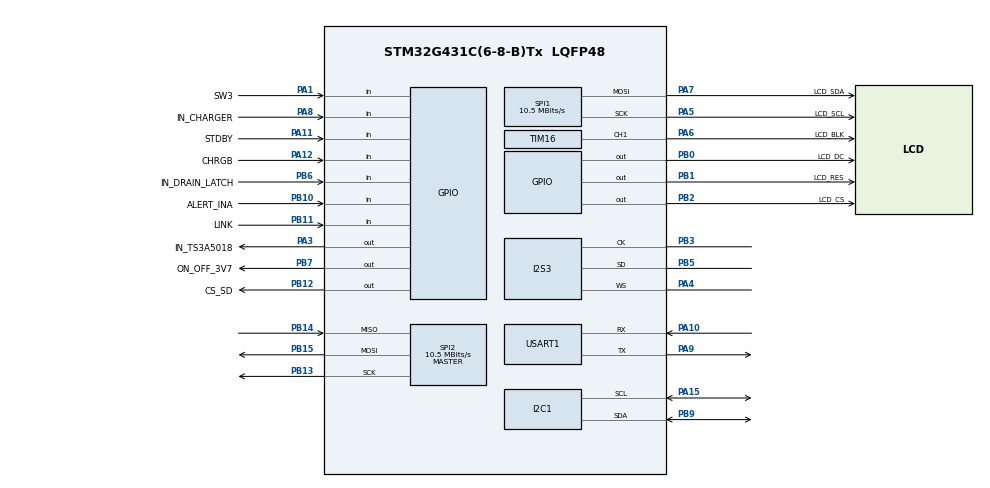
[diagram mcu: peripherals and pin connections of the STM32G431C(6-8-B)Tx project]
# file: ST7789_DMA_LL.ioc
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Dma.Request0=SPI1_TX
Dma.SPI1_TX.0.Direction=DMA_MEMORY_TO_PERIPH
Dma.SPI1_TX.0.EventEnable=DISABLE
Dma.SPI1_TX.0.Instance=DMA1_Channel1
Dma.SPI1_TX.0.MemDataAlignment=DMA_MDATAALIGN_HALFWORD
Dma.SPI1_TX.0.MemInc=DMA_MINC_ENABLE
Dma.SPI1_TX.0.Mode=DMA_NORMAL
Dma.SPI1_TX.0.PeriphDataAlignment=DMA_PDATAALIGN_HALFWORD
Dma.SPI1_TX.0.PeriphInc=DMA_PINC_DISABLE
Dma.SPI1_TX.0.Polarity=HAL_DMAMUX_REQ_GEN_RISING
Dma.SPI1_TX.0.Priority=DMA_PRIORITY_LOW
Dma.SPI1_TX.0.RequestNumber=1
Dma.SPI1_TX.0.SignalID=NONE
Dma.SPI1_TX.0.SyncEnable=DISABLE
Dma.SPI1_TX.0.SyncPolarity=HAL_DMAMUX_SYNC_NO_EVENT
Dma.SPI1_TX.0.SyncRequestNumber=1
Dma.SPI1_TX.0.SyncSignalID=NONE
FATFS._MAX_SS=4096
FATFS._USE_LFN=1
I2C1.Timing=0x20916F9D
I2S3.AudioFreq=I2S_AUDIOFREQ_44K
I2S3.ErrorAudioFreq=-0.56 %
I2S3.FullDuplexMode=I2S_FULLDUPLEXMODE_DISABLE
I2S3.Instance=SPI$Index
I2S3.RealAudioFreq=43.75 KHz
I2S3.VirtualMode=I2S_MODE_MASTER
Mcu.Family=STM32G4
Mcu.Name=STM32G431C(6-8-B)Tx
Mcu.Package=LQFP48
NVIC.DMA1_Channel1_IRQn=true\:0\:0\:false\:false\:true\:false\:true\:true
NVIC.PriorityGroup=NVIC_PRIORITYGROUP_4
PA0.Mode=SYS_WakeUp0
PA0.Signal=SYS_WKUP1
PA1.GPIO_Label=SW3
PA1.Signal=GPIO_Input
PA10.Mode=Asynchronous
PA10.Signal=USART1_RX
PA11.GPIO_Label=STDBY
PA11.Signal=GPIO_Input
PA12.GPIO_Label=CHRGB
PA12.Signal=GPIO_Input
PA13.Mode=Serial_Wire
PA13.Signal=SYS_JTMS-SWDIO
PA14.Mode=Serial_Wire
PA14.Signal=SYS_JTCK-SWCLK
PA15.Mode=I2C
PA15.Signal=I2C1_SCL
PA2.Mode=SYS_WakeUp3
PA2.Signal=SYS_WKUP4
PA3.GPIO_Label=IN_TS3A5018
PA3.Signal=GPIO_Output
PA4.Mode=Half_Duplex_Master
PA4.Signal=I2S3_WS
PA5.GPIO_Label=LCD_SCL
PA5.Mode=TX_Only_Simplex_Unidirect_Master
PA5.Signal=SPI1_SCK
PA6.GPIO_Label=LCD_BLK
PA6.Signal=S_TIM16_CH1
PA7.GPIO_Label=LCD_SDA
PA7.Mode=TX_Only_Simplex_Unidirect_Master
PA7.Signal=SPI1_MOSI
PA8.GPIO_Label=IN_CHARGER
PA8.Signal=GPIO_Input
PA9.Mode=Asynchronous
PA9.Signal=USART1_TX
PB0.GPIO_Label=LCD_DC
PB0.GPIO_Speed=GPIO_SPEED_FREQ_VERY_HIGH
PB0.Signal=GPIO_Output
PB1.GPIO_Label=LCD_RES
PB1.GPIO_Speed=GPIO_SPEED_FREQ_VERY_HIGH
PB1.Signal=GPIO_Output
PB10.GPIO_Label=ALERT_INA
PB10.GPIO_PuPd=GPIO_PULLUP
PB10.Signal=GPIO_Input
PB11.GPIO_Label=LINK
PB11.Signal=GPIO_Input
PB12.GPIO_Label=CS_SD
PB12.Signal=GPIO_Output
PB13.Mode=Full_Duplex_Master
PB13.Signal=SPI2_SCK
PB14.Mode=Full_Duplex_Master
PB14.Signal=SPI2_MISO
PB15.Mode=Full_Duplex_Master
PB15.Signal=SPI2_MOSI
PB2.GPIO_Label=LCD_CS
PB2.GPIO_Speed=GPIO_SPEED_FREQ_VERY_HIGH
PB2.PinState=GPIO_PIN_SET
PB2.Signal=GPIO_Output
PB3.Mode=Half_Duplex_Master
PB3.Signal=I2S3_CK
PB5.Mode=Half_Duplex_Master
PB5.Signal=I2S3_SD
PB6.GPIO_Label=IN_DRAIN_LATCH
PB6.Signal=GPIO_Input
PB7.GPIO_Label=ON_OFF_3V7
PB7.Signal=GPIO_Output
PB9.Mode=I2C
PB9.Signal=I2C1_SDA
PC13.Mode=SYS_WakeUp1
PC13.Signal=SYS_WKUP2
PF0-OSC_IN.Mode=HSE-External-Oscillator
PF0-OSC_IN.Signal=RCC_OSC_IN
PF1-OSC_OUT.Mode=HSE-External-Oscillator
PF1-OSC_OUT.Signal=RCC_OSC_OUT
ProjectManager.HeapSize=0x200
ProjectManager.StackSize=0x400
ProjectManager.TargetToolchain=STM32CubeIDE
RCC.ADC12Freq_Value=84000000
RCC.AHBFreq_Value=84000000
RCC.APB1Freq_Value=84000000
RCC.APB1TimFreq_Value=84000000
RCC.APB2Freq_Value=84000000
RCC.APB2TimFreq_Value=84000000
RCC.CortexFreq_Value=84000000
RCC.EXTERNAL_CLOCK_VALUE=12288000
RCC.HCLKFreq_Value=84000000
RCC.HSE_VALUE=20000000
RCC.HSI48_VALUE=48000000
RCC.HSI_VALUE=16000000
RCC.LSE_VALUE=32768
RCC.PLLM=RCC_PLLM_DIV5
RCC.PLLN=42
RCC.PLLSourceVirtual=RCC_PLLSOURCE_HSE
RCC.SYSCLKFreq_VALUE=84000000
RCC.SYSCLKSource=RCC_SYSCLKSOURCE_PLLCLK
RCC.USBFreq_Value=84000000
RCC.VCOOutputFreq_Value=168000000
SH.S_TIM16_CH1.0=TIM16_CH1,PWM Generation1 CH1
SPI1.BaudRatePrescaler=SPI_BAUDRATEPRESCALER_8
SPI1.CLKPhase=SPI_PHASE_1EDGE
SPI1.CLKPolarity=SPI_POLARITY_HIGH
SPI1.CalculateBaudRate=10.5 MBits/s
SPI1.DataSize=SPI_DATASIZE_16BIT
SPI1.Direction=SPI_DIRECTION_2LINES
SPI1.Mode=SPI_MODE_MASTER
SPI1.VirtualType=VM_MASTER
SPI2.BaudRatePrescaler=SPI_BAUDRATEPRESCALER_8
SPI2.CalculateBaudRate=10.5 MBits/s
SPI2.DataSize=SPI_DATASIZE_8BIT
SPI2.Direction=SPI_DIRECTION_2LINES
SPI2.Mode=SPI_MODE_MASTER
SPI2.VirtualType=VM_MASTER
TIM16.Channel=TIM_CHANNEL_1
TIM16.PeriodNoDither=210-1
TIM16.Prescaler=1000-1
TIM16.PulseNoDither_1=210-1
USART1.VirtualMode-Asynchronous=VM_ASYNC
VP_FATFS_VS_Generic.Mode=User_defined
VP_TIM16_VS_ClockSourceINT.Mode=Enable_Timer
board=custom

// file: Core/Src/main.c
/* USER CODE BEGIN Header */
/**
  ******************************************************************************
  * @file           : main.c
  * @brief          : Main program body
  ******************************************************************************
  * @attention
  *
  * Copyright (c) 2025 STMicroelectronics.
  * All rights reserved.
  *
  * This software is licensed under terms that can be found in the LICENSE file
  * in the root directory of this software component.
  * If no LICENSE file comes with this software, it is provided AS-IS.
  *
  ******************************************************************************
  */
/* USER CODE END Header */
#include "main.h"
#include "app_fatfs.h"

/* USER CODE BEGIN Includes */
#include "display.h"
#include "st7789.h"
/* USER CODE END Includes */

I2C_HandleTypeDef hi2c1;

I2S_HandleTypeDef hi2s3;

UART_HandleTypeDef huart1;

void SystemClock_Config(void);
static void MX_GPIO_Init(void);
static void MX_DMA_Init(void);
static void MX_I2C1_Init(void);
static void MX_SPI1_Init(void);
static void MX_TIM16_Init(void);
static void MX_SPI2_Init(void);
static void MX_I2S3_Init(void);
static void MX_USART1_UART_Init(void);

int main(void)
{

  /* MCU Configuration--------------------------------------------------------*/

  /* Reset of all peripherals, Initializes the Flash interface and the Systick. */
  HAL_Init();

  /* Configure the system clock */
  SystemClock_Config();

  /* Initialize all configured peripherals */
  MX_GPIO_Init();
  MX_DMA_Init();
  MX_I2C1_Init();
  MX_SPI1_Init();
  MX_TIM16_Init();
  MX_SPI2_Init();
  MX_I2S3_Init();
  MX_USART1_UART_Init();
  if (MX_FATFS_Init() != APP_OK) {
    Error_Handler();
  }

  /* Infinite loop */
  while (1)
  {

  }
}

void SystemClock_Config(void)
{
  LL_FLASH_SetLatency(LL_FLASH_LATENCY_2);
  while(LL_FLASH_GetLatency() != LL_FLASH_LATENCY_2)
  {
  }
  LL_PWR_SetRegulVoltageScaling(LL_PWR_REGU_VOLTAGE_SCALE1);
  LL_RCC_HSE_Enable();
   /* Wait till HSE is ready */
  while(LL_RCC_HSE_IsReady() != 1)
  {
  }

  LL_RCC_PLL_ConfigDomain_SYS(LL_RCC_PLLSOURCE_HSE, LL_RCC_PLLM_DIV_5, 42, LL_RCC_PLLR_DIV_2);
  LL_RCC_PLL_EnableDomain_SYS();
  LL_RCC_PLL_Enable();
   /* Wait till PLL is ready */
  while(LL_RCC_PLL_IsReady() != 1)
  {
  }

  LL_RCC_SetSysClkSource(LL_RCC_SYS_CLKSOURCE_PLL);
  LL_RCC_SetAHBPrescaler(LL_RCC_SYSCLK_DIV_2);
   /* Wait till System clock is ready */
  while(LL_RCC_GetSysClkSource() != LL_RCC_SYS_CLKSOURCE_STATUS_PLL)
  {
  }

  /* Insure 1us transition state at intermediate medium speed clock*/
  for (__IO uint32_t i = (170 >> 1); i !=0; i--);

  /* Set AHB prescaler*/
  LL_RCC_SetAHBPrescaler(LL_RCC_SYSCLK_DIV_1);
  LL_RCC_SetAPB1Prescaler(LL_RCC_APB1_DIV_1);
  LL_RCC_SetAPB2Prescaler(LL_RCC_APB2_DIV_1);
  LL_SetSystemCoreClock(84000000);

   /* Update the time base */
  if (HAL_InitTick (TICK_INT_PRIORITY) != HAL_OK)
  {
    Error_Handler();
  }
}

static void MX_I2C1_Init(void)
{

  hi2c1.Instance = I2C1;
  hi2c1.Init.Timing = 0x20916F9D;
  hi2c1.Init.OwnAddress1 = 0;
  hi2c1.Init.AddressingMode = I2C_ADDRESSINGMODE_7BIT;
  hi2c1.Init.DualAddressMode = I2C_DUALADDRESS_DISABLE;
  hi2c1.Init.OwnAddress2 = 0;
  hi2c1.Init.OwnAddress2Masks = I2C_OA2_NOMASK;
  hi2c1.Init.GeneralCallMode = I2C_GENERALCALL_DISABLE;
  hi2c1.Init.NoStretchMode = I2C_NOSTRETCH_DISABLE;
  if (HAL_I2C_Init(&hi2c1) != HAL_OK)
  {
    Error_Handler();
  }

  /** Configure Analogue filter
  */
  if (HAL_I2CEx_ConfigAnalogFilter(&hi2c1, I2C_ANALOGFILTER_ENABLE) != HAL_OK)
  {
    Error_Handler();
  }

  /** Configure Digital filter
  */
  if (HAL_I2CEx_ConfigDigitalFilter(&hi2c1, 0) != HAL_OK)
  {
    Error_Handler();
  }

}

static void MX_I2S3_Init(void)
{

  hi2s3.Instance = SPI3;
  hi2s3.Init.Mode = I2S_MODE_MASTER_TX;
  hi2s3.Init.Standard = I2S_STANDARD_PHILIPS;
  hi2s3.Init.DataFormat = I2S_DATAFORMAT_16B;
  hi2s3.Init.MCLKOutput = I2S_MCLKOUTPUT_DISABLE;
  hi2s3.Init.AudioFreq = I2S_AUDIOFREQ_44K;
  hi2s3.Init.CPOL = I2S_CPOL_LOW;
  if (HAL_I2S_Init(&hi2s3) != HAL_OK)
  {
    Error_Handler();
  }

}

static void MX_SPI1_Init(void)
{

  LL_SPI_InitTypeDef SPI_InitStruct = {0};

  LL_GPIO_InitTypeDef GPIO_InitStruct = {0};

  /* Peripheral clock enable */
  LL_APB2_GRP1_EnableClock(LL_APB2_GRP1_PERIPH_SPI1);

  LL_AHB2_GRP1_EnableClock(LL_AHB2_GRP1_PERIPH_GPIOA);
  /**SPI1 GPIO Configuration
  PA5   ------> SPI1_SCK
  PA7   ------> SPI1_MOSI
  */
  GPIO_InitStruct.Pin = LCD_SCL_Pin;
  GPIO_InitStruct.Mode = LL_GPIO_MODE_ALTERNATE;
  GPIO_InitStruct.Speed = LL_GPIO_SPEED_FREQ_LOW;
  GPIO_InitStruct.OutputType = LL_GPIO_OUTPUT_PUSHPULL;
  GPIO_InitStruct.Pull = LL_GPIO_PULL_NO;
  GPIO_InitStruct.Alternate = LL_GPIO_AF_5;
  LL_GPIO_Init(LCD_SCL_GPIO_Port, &GPIO_InitStruct);

  GPIO_InitStruct.Pin = LCD_SDA_Pin;
  GPIO_InitStruct.Mode = LL_GPIO_MODE_ALTERNATE;
  GPIO_InitStruct.Speed = LL_GPIO_SPEED_FREQ_LOW;
  GPIO_InitStruct.OutputType = LL_GPIO_OUTPUT_PUSHPULL;
  GPIO_InitStruct.Pull = LL_GPIO_PULL_NO;
  GPIO_InitStruct.Alternate = LL_GPIO_AF_5;
  LL_GPIO_Init(LCD_SDA_GPIO_Port, &GPIO_InitStruct);

  /* SPI1 DMA Init */

  /* SPI1_TX Init */
  LL_DMA_SetPeriphRequest(DMA1, LL_DMA_CHANNEL_1, LL_DMAMUX_REQ_SPI1_TX);

  LL_DMA_SetDataTransferDirection(DMA1, LL_DMA_CHANNEL_1, LL_DMA_DIRECTION_MEMORY_TO_PERIPH);

  LL_DMA_SetChannelPriorityLevel(DMA1, LL_DMA_CHANNEL_1, LL_DMA_PRIORITY_LOW);

  LL_DMA_SetMode(DMA1, LL_DMA_CHANNEL_1, LL_DMA_MODE_NORMAL);

  LL_DMA_SetPeriphIncMode(DMA1, LL_DMA_CHANNEL_1, LL_DMA_PERIPH_NOINCREMENT);

  LL_DMA_SetMemoryIncMode(DMA1, LL_DMA_CHANNEL_1, LL_DMA_MEMORY_INCREMENT);

  LL_DMA_SetPeriphSize(DMA1, LL_DMA_CHANNEL_1, LL_DMA_PDATAALIGN_HALFWORD);

  LL_DMA_SetMemorySize(DMA1, LL_DMA_CHANNEL_1, LL_DMA_MDATAALIGN_HALFWORD);

  /* SPI1 parameter configuration*/
  SPI_InitStruct.TransferDirection = LL_SPI_FULL_DUPLEX;
  SPI_InitStruct.Mode = LL_SPI_MODE_MASTER;
  SPI_InitStruct.DataWidth = LL_SPI_DATAWIDTH_16BIT;
  SPI_InitStruct.ClockPolarity = LL_SPI_POLARITY_HIGH;
  SPI_InitStruct.ClockPhase = LL_SPI_PHASE_1EDGE;
  SPI_InitStruct.NSS = LL_SPI_NSS_SOFT;
  SPI_InitStruct.BaudRate = LL_SPI_BAUDRATEPRESCALER_DIV8;
  SPI_InitStruct.BitOrder = LL_SPI_MSB_FIRST;
  SPI_InitStruct.CRCCalculation = LL_SPI_CRCCALCULATION_DISABLE;
  SPI_InitStruct.CRCPoly = 7;
  LL_SPI_Init(SPI1, &SPI_InitStruct);
  LL_SPI_SetStandard(SPI1, LL_SPI_PROTOCOL_MOTOROLA);
  LL_SPI_EnableNSSPulseMgt(SPI1);

}

static void MX_SPI2_Init(void)
{

  LL_SPI_InitTypeDef SPI_InitStruct = {0};

  LL_GPIO_InitTypeDef GPIO_InitStruct = {0};

  /* Peripheral clock enable */
  LL_APB1_GRP1_EnableClock(LL_APB1_GRP1_PERIPH_SPI2);

  LL_AHB2_GRP1_EnableClock(LL_AHB2_GRP1_PERIPH_GPIOB);
  /**SPI2 GPIO Configuration
  PB13   ------> SPI2_SCK
  PB14   ------> SPI2_MISO
  PB15   ------> SPI2_MOSI
  */
  GPIO_InitStruct.Pin = LL_GPIO_PIN_13;
  GPIO_InitStruct.Mode = LL_GPIO_MODE_ALTERNATE;
  GPIO_InitStruct.Speed = LL_GPIO_SPEED_FREQ_LOW;
  GPIO_InitStruct.OutputType = LL_GPIO_OUTPUT_PUSHPULL;
  GPIO_InitStruct.Pull = LL_GPIO_PULL_NO;
  GPIO_InitStruct.Alternate = LL_GPIO_AF_5;
  LL_GPIO_Init(GPIOB, &GPIO_InitStruct);

  GPIO_InitStruct.Pin = LL_GPIO_PIN_14;
  GPIO_InitStruct.Mode = LL_GPIO_MODE_ALTERNATE;
  GPIO_InitStruct.Speed = LL_GPIO_SPEED_FREQ_LOW;
  GPIO_InitStruct.OutputType = LL_GPIO_OUTPUT_PUSHPULL;
  GPIO_InitStruct.Pull = LL_GPIO_PULL_NO;
  GPIO_InitStruct.Alternate = LL_GPIO_AF_5;
  LL_GPIO_Init(GPIOB, &GPIO_InitStruct);

  GPIO_InitStruct.Pin = LL_GPIO_PIN_15;
  GPIO_InitStruct.Mode = LL_GPIO_MODE_ALTERNATE;
  GPIO_InitStruct.Speed = LL_GPIO_SPEED_FREQ_LOW;
  GPIO_InitStruct.OutputType = LL_GPIO_OUTPUT_PUSHPULL;
  GPIO_InitStruct.Pull = LL_GPIO_PULL_NO;
  GPIO_InitStruct.Alternate = LL_GPIO_AF_5;
  LL_GPIO_Init(GPIOB, &GPIO_InitStruct);

  /* SPI2 parameter configuration*/
  SPI_InitStruct.TransferDirection = LL_SPI_FULL_DUPLEX;
  SPI_InitStruct.Mode = LL_SPI_MODE_MASTER;
  SPI_InitStruct.DataWidth = LL_SPI_DATAWIDTH_8BIT;
  SPI_InitStruct.ClockPolarity = LL_SPI_POLARITY_LOW;
  SPI_InitStruct.ClockPhase = LL_SPI_PHASE_1EDGE;
  SPI_InitStruct.NSS = LL_SPI_NSS_SOFT;
  SPI_InitStruct.BaudRate = LL_SPI_BAUDRATEPRESCALER_DIV8;
  SPI_InitStruct.BitOrder = LL_SPI_MSB_FIRST;
  SPI_InitStruct.CRCCalculation = LL_SPI_CRCCALCULATION_DISABLE;
  SPI_InitStruct.CRCPoly = 7;
  LL_SPI_Init(SPI2, &SPI_InitStruct);
  LL_SPI_SetStandard(SPI2, LL_SPI_PROTOCOL_MOTOROLA);
  LL_SPI_EnableNSSPulseMgt(SPI2);

}

static void MX_TIM16_Init(void)
{

  LL_TIM_InitTypeDef TIM_InitStruct = {0};
  LL_TIM_OC_InitTypeDef TIM_OC_InitStruct = {0};
  LL_TIM_BDTR_InitTypeDef TIM_BDTRInitStruct = {0};

  LL_GPIO_InitTypeDef GPIO_InitStruct = {0};

  /* Peripheral clock enable */
  LL_APB2_GRP1_EnableClock(LL_APB2_GRP1_PERIPH_TIM16);

  TIM_InitStruct.Prescaler = 999;
  TIM_InitStruct.CounterMode = LL_TIM_COUNTERMODE_UP;
  TIM_InitStruct.Autoreload = 209;
  TIM_InitStruct.ClockDivision = LL_TIM_CLOCKDIVISION_DIV1;
  TIM_InitStruct.RepetitionCounter = 0;
  LL_TIM_Init(TIM16, &TIM_InitStruct);
  LL_TIM_DisableARRPreload(TIM16);
  LL_TIM_OC_EnablePreload(TIM16, LL_TIM_CHANNEL_CH1);
  TIM_OC_InitStruct.OCMode = LL_TIM_OCMODE_PWM1;
  TIM_OC_InitStruct.OCState = LL_TIM_OCSTATE_DISABLE;
  TIM_OC_InitStruct.OCNState = LL_TIM_OCSTATE_DISABLE;
  TIM_OC_InitStruct.CompareValue = 209;
  TIM_OC_InitStruct.OCPolarity = LL_TIM_OCPOLARITY_HIGH;
  TIM_OC_InitStruct.OCNPolarity = LL_TIM_OCPOLARITY_HIGH;
  TIM_OC_InitStruct.OCIdleState = LL_TIM_OCIDLESTATE_LOW;
  TIM_OC_InitStruct.OCNIdleState = LL_TIM_OCIDLESTATE_LOW;
  LL_TIM_OC_Init(TIM16, LL_TIM_CHANNEL_CH1, &TIM_OC_InitStruct);
  LL_TIM_OC_DisableFast(TIM16, LL_TIM_CHANNEL_CH1);
  TIM_BDTRInitStruct.OSSRState = LL_TIM_OSSR_DISABLE;
  TIM_BDTRInitStruct.OSSIState = LL_TIM_OSSI_DISABLE;
  TIM_BDTRInitStruct.LockLevel = LL_TIM_LOCKLEVEL_OFF;
  TIM_BDTRInitStruct.DeadTime = 0;
  TIM_BDTRInitStruct.BreakState = LL_TIM_BREAK_DISABLE;
  TIM_BDTRInitStruct.BreakPolarity = LL_TIM_BREAK_POLARITY_HIGH;
  TIM_BDTRInitStruct.BreakFilter = LL_TIM_BREAK_FILTER_FDIV1;
  TIM_BDTRInitStruct.AutomaticOutput = LL_TIM_AUTOMATICOUTPUT_DISABLE;
  LL_TIM_BDTR_Init(TIM16, &TIM_BDTRInitStruct);
  LL_AHB2_GRP1_EnableClock(LL_AHB2_GRP1_PERIPH_GPIOA);
  /**TIM16 GPIO Configuration
  PA6   ------> TIM16_CH1
  */
  GPIO_InitStruct.Pin = LCD_BLK_Pin;
  GPIO_InitStruct.Mode = LL_GPIO_MODE_ALTERNATE;
  GPIO_InitStruct.Speed = LL_GPIO_SPEED_FREQ_LOW;
  GPIO_InitStruct.OutputType = LL_GPIO_OUTPUT_PUSHPULL;
  GPIO_InitStruct.Pull = LL_GPIO_PULL_NO;
  GPIO_InitStruct.Alternate = LL_GPIO_AF_1;
  LL_GPIO_Init(LCD_BLK_GPIO_Port, &GPIO_InitStruct);

}

static void MX_USART1_UART_Init(void)
{

  huart1.Instance = USART1;
  huart1.Init.BaudRate = 115200;
  huart1.Init.WordLength = UART_WORDLENGTH_8B;
  huart1.Init.StopBits = UART_STOPBITS_1;
  huart1.Init.Parity = UART_PARITY_NONE;
  huart1.Init.Mode = UART_MODE_TX_RX;
  huart1.Init.HwFlowCtl = UART_HWCONTROL_NONE;
  huart1.Init.OverSampling = UART_OVERSAMPLING_16;
  huart1.Init.OneBitSampling = UART_ONE_BIT_SAMPLE_DISABLE;
  huart1.Init.ClockPrescaler = UART_PRESCALER_DIV1;
  huart1.AdvancedInit.AdvFeatureInit = UART_ADVFEATURE_NO_INIT;
  if (HAL_UART_Init(&huart1) != HAL_OK)
  {
    Error_Handler();
  }
  if (HAL_UARTEx_SetTxFifoThreshold(&huart1, UART_TXFIFO_THRESHOLD_1_8) != HAL_OK)
  {
    Error_Handler();
  }
  if (HAL_UARTEx_SetRxFifoThreshold(&huart1, UART_RXFIFO_THRESHOLD_1_8) != HAL_OK)
  {
    Error_Handler();
  }
  if (HAL_UARTEx_DisableFifoMode(&huart1) != HAL_OK)
  {
    Error_Handler();
  }

}

static void MX_DMA_Init(void)
{

  /* Init with LL driver */
  /* DMA controller clock enable */
  LL_AHB1_GRP1_EnableClock(LL_AHB1_GRP1_PERIPH_DMAMUX1);
  LL_AHB1_GRP1_EnableClock(LL_AHB1_GRP1_PERIPH_DMA1);

  /* DMA interrupt init */
  /* DMA1_Channel1_IRQn interrupt configuration */
  NVIC_SetPriority(DMA1_Channel1_IRQn, NVIC_EncodePriority(NVIC_GetPriorityGrouping(),0, 0));
  NVIC_EnableIRQ(DMA1_Channel1_IRQn);

}

static void MX_GPIO_Init(void)
{
  LL_GPIO_InitTypeDef GPIO_InitStruct = {0};

  /* GPIO Ports Clock Enable */
  LL_AHB2_GRP1_EnableClock(LL_AHB2_GRP1_PERIPH_GPIOC);
  LL_AHB2_GRP1_EnableClock(LL_AHB2_GRP1_PERIPH_GPIOF);
  LL_AHB2_GRP1_EnableClock(LL_AHB2_GRP1_PERIPH_GPIOA);
  LL_AHB2_GRP1_EnableClock(LL_AHB2_GRP1_PERIPH_GPIOB);

  /**/
  LL_GPIO_ResetOutputPin(IN_TS3A5018_GPIO_Port, IN_TS3A5018_Pin);

  /**/
  LL_GPIO_ResetOutputPin(LCD_DC_GPIO_Port, LCD_DC_Pin);

  /**/
  LL_GPIO_ResetOutputPin(LCD_RES_GPIO_Port, LCD_RES_Pin);

  /**/
  LL_GPIO_ResetOutputPin(CS_SD_GPIO_Port, CS_SD_Pin);

  /**/
  LL_GPIO_ResetOutputPin(ON_OFF_3V7_GPIO_Port, ON_OFF_3V7_Pin);

  /**/
  LL_GPIO_SetOutputPin(LCD_CS_GPIO_Port, LCD_CS_Pin);

  /**/
  GPIO_InitStruct.Pin = SW3_Pin;
  GPIO_InitStruct.Mode = LL_GPIO_MODE_INPUT;
  GPIO_InitStruct.Pull = LL_GPIO_PULL_NO;
  LL_GPIO_Init(SW3_GPIO_Port, &GPIO_InitStruct);

  /**/
  GPIO_InitStruct.Pin = IN_TS3A5018_Pin;
  GPIO_InitStruct.Mode = LL_GPIO_MODE_OUTPUT;
  GPIO_InitStruct.Speed = LL_GPIO_SPEED_FREQ_LOW;
  GPIO_InitStruct.OutputType = LL_GPIO_OUTPUT_PUSHPULL;
  GPIO_InitStruct.Pull = LL_GPIO_PULL_NO;
  LL_GPIO_Init(IN_TS3A5018_GPIO_Port, &GPIO_InitStruct);

  /**/
  GPIO_InitStruct.Pin = LCD_DC_Pin;
  GPIO_InitStruct.Mode = LL_GPIO_MODE_OUTPUT;
  GPIO_InitStruct.Speed = LL_GPIO_SPEED_FREQ_VERY_HIGH;
  GPIO_InitStruct.OutputType = LL_GPIO_OUTPUT_PUSHPULL;
  GPIO_InitStruct.Pull = LL_GPIO_PULL_NO;
  LL_GPIO_Init(LCD_DC_GPIO_Port, &GPIO_InitStruct);

  /**/
  GPIO_InitStruct.Pin = LCD_RES_Pin;
  GPIO_InitStruct.Mode = LL_GPIO_MODE_OUTPUT;
  GPIO_InitStruct.Speed = LL_GPIO_SPEED_FREQ_VERY_HIGH;
  GPIO_InitStruct.OutputType = LL_GPIO_OUTPUT_PUSHPULL;
  GPIO_InitStruct.Pull = LL_GPIO_PULL_NO;
  LL_GPIO_Init(LCD_RES_GPIO_Port, &GPIO_InitStruct);

  /**/
  GPIO_InitStruct.Pin = LCD_CS_Pin;
  GPIO_InitStruct.Mode = LL_GPIO_MODE_OUTPUT;
  GPIO_InitStruct.Speed = LL_GPIO_SPEED_FREQ_VERY_HIGH;
  GPIO_InitStruct.OutputType = LL_GPIO_OUTPUT_PUSHPULL;
  GPIO_InitStruct.Pull = LL_GPIO_PULL_NO;
  LL_GPIO_Init(LCD_CS_GPIO_Port, &GPIO_InitStruct);

  /**/
  GPIO_InitStruct.Pin = ALERT_INA_Pin;
  GPIO_InitStruct.Mode = LL_GPIO_MODE_INPUT;
  GPIO_InitStruct.Pull = LL_GPIO_PULL_UP;
  LL_GPIO_Init(ALERT_INA_GPIO_Port, &GPIO_InitStruct);

  /**/
  GPIO_InitStruct.Pin = LINK_Pin;
  GPIO_InitStruct.Mode = LL_GPIO_MODE_INPUT;
  GPIO_InitStruct.Pull = LL_GPIO_PULL_NO;
  LL_GPIO_Init(LINK_GPIO_Port, &GPIO_InitStruct);

  /**/
  GPIO_InitStruct.Pin = CS_SD_Pin;
  GPIO_InitStruct.Mode = LL_GPIO_MODE_OUTPUT;
  GPIO_InitStruct.Speed = LL_GPIO_SPEED_FREQ_LOW;
  GPIO_InitStruct.OutputType = LL_GPIO_OUTPUT_PUSHPULL;
  GPIO_InitStruct.Pull = LL_GPIO_PULL_NO;
  LL_GPIO_Init(CS_SD_GPIO_Port, &GPIO_InitStruct);

  /**/
  GPIO_InitStruct.Pin = IN_CHARGER_Pin;
  GPIO_InitStruct.Mode = LL_GPIO_MODE_INPUT;
  GPIO_InitStruct.Pull = LL_GPIO_PULL_NO;
  LL_GPIO_Init(IN_CHARGER_GPIO_Port, &GPIO_InitStruct);

  /**/
  GPIO_InitStruct.Pin = STDBY_Pin;
  GPIO_InitStruct.Mode = LL_GPIO_MODE_INPUT;
  GPIO_InitStruct.Pull = LL_GPIO_PULL_NO;
  LL_GPIO_Init(STDBY_GPIO_Port, &GPIO_InitStruct);

  /**/
  GPIO_InitStruct.Pin = CHRGB_Pin;
  GPIO_InitStruct.Mode = LL_GPIO_MODE_INPUT;
  GPIO_InitStruct.Pull = LL_GPIO_PULL_NO;
  LL_GPIO_Init(CHRGB_GPIO_Port, &GPIO_InitStruct);

  /**/
  GPIO_InitStruct.Pin = IN_DRAIN_LATCH_Pin;
  GPIO_InitStruct.Mode = LL_GPIO_MODE_INPUT;
  GPIO_InitStruct.Pull = LL_GPIO_PULL_NO;
  LL_GPIO_Init(IN_DRAIN_LATCH_GPIO_Port, &GPIO_InitStruct);

  /**/
  GPIO_InitStruct.Pin = ON_OFF_3V7_Pin;
  GPIO_InitStruct.Mode = LL_GPIO_MODE_OUTPUT;
  GPIO_InitStruct.Speed = LL_GPIO_SPEED_FREQ_LOW;
  GPIO_InitStruct.OutputType = LL_GPIO_OUTPUT_PUSHPULL;
  GPIO_InitStruct.Pull = LL_GPIO_PULL_NO;
  LL_GPIO_Init(ON_OFF_3V7_GPIO_Port, &GPIO_InitStruct);

}

void Error_Handler(void)
{
  __disable_irq();
  while (1)
  {
  }
}
